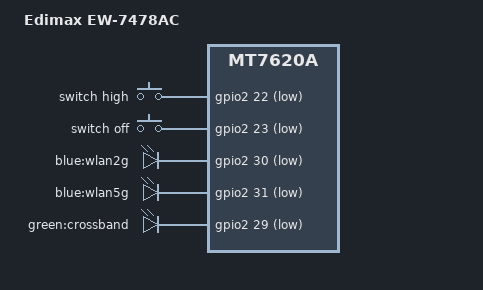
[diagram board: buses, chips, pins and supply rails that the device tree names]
// SPDX-License-Identifier: GPL-2.0-or-later OR MIT

#include "mt7620a_edimax_ew-747x.dtsi"

/ {
	compatible = "edimax,ew-7478ac", "ralink,mt7620a-soc";
	model = "Edimax EW-7478AC";

	keys {
		switch_high {
			label = "switch high";
			gpios = <&gpio2 22 GPIO_ACTIVE_LOW>;
			linux,code = <BTN_0>;
			linux,input-type = <EV_SW>;
		};

		switch_off {
			label = "switch off";
			gpios = <&gpio2 23 GPIO_ACTIVE_LOW>;
			linux,code = <BTN_1>;
			linux,input-type = <EV_SW>;
		};
	};

	leds {
		wlan2g {
			label = "blue:wlan2g";
			gpios = <&gpio2 30 GPIO_ACTIVE_LOW>;
			linux,default-trigger = "phy1radio";
		};

		wlan5g {
			label = "blue:wlan5g";
			gpios = <&gpio2 31 GPIO_ACTIVE_LOW>;
			linux,default-trigger = "phy0radio";
		};

		crossband {
			label = "green:crossband";
			gpios = <&gpio2 29 GPIO_ACTIVE_LOW>;
		};
	};
};
